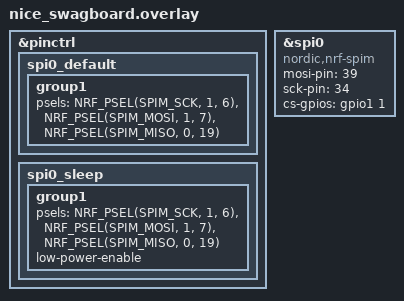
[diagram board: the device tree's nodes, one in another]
&pinctrl {
    spi0_default: spi0_default {
        group1 {
            psels = <NRF_PSEL(SPIM_SCK, 1, 6)>,
                <NRF_PSEL(SPIM_MOSI, 1, 7)>,
                <NRF_PSEL(SPIM_MISO, 0, 19)>; /* GPIO0 19 is not broken on a nice!nano.*/
        };
    };
    spi0_sleep: spi0_sleep {
        group1 {
            psels = <NRF_PSEL(SPIM_SCK, 1, 6)>,
                <NRF_PSEL(SPIM_MOSI, 1, 7)>,
                <NRF_PSEL(SPIM_MISO, 0, 19)>; /* GPIO0 19 is not broken on a nice!nano.*/
            low-power-enable;
        };
    };
};

nice_view_spi: &spi0 {
    compatible = "nordic,nrf-spim";
   
    mosi-pin = <39>;
    
    sck-pin = <34>;
    
    cs-gpios = <&gpio1 1 GPIO_ACTIVE_HIGH>;
};

